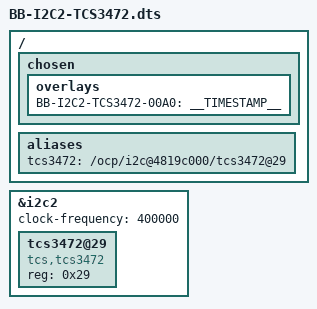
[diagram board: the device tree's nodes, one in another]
/dts-v1/;
/plugin/;

/ {
	/*
	 * Helper to show loaded overlays under: /proc/device-tree/chosen/overlays/
	 */
	fragment@0 {
		target-path="/";
		__overlay__ {
			chosen {
				overlays {
					BB-I2C2-TCS3472-00A0 = __TIMESTAMP__;
				};
			};
		};
	};

	fragment@1 {
		target-path="/";
		__overlay__ {

			aliases {
				/* SLOT I2C1 */
				/*
				tcs3472 = "/ocp/i2c@4802a000/tcs3472@29";
				*/
				/* SLOT I2C2 */
				tcs3472 = "/ocp/i2c@4819c000/tcs3472@29";
			};
		};
	};

	fragment@2 {
		/* SLOT I2C1 */
		/*
		target = <&i2c1>;
		*/
		/* SLOT I2C2 */
		target = <&i2c2>;

		__overlay__ {
			status = "okay";

			clock-frequency = <400000>;

			#address-cells = <1>;
			#size-cells = <0>;

			tcs3472@29 {
				compatible = "tcs,tcs3472";
				reg = <0x29>;
				status = "okay";
			};
		};
	};
};

